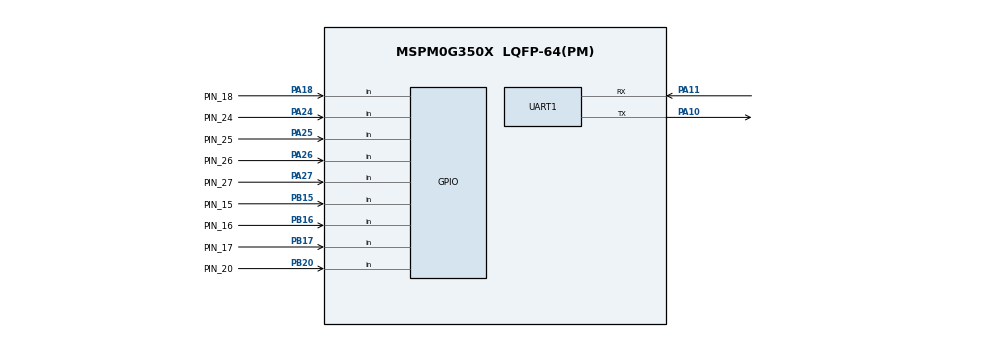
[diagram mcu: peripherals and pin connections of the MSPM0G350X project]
/**
 *
 * @cliArgs --device "MSPM0G350X" --part "Default" --package "LQFP-64(PM)" --product "mspm0_sdk@2.10.00.04"
 * @versions {"tool":"1.28.0+4696"}
 */

/**
 * Import the modules used in this configuration.
 */
const GPIO    = scripting.addModule("/ti/driverlib/GPIO", {}, false);
const GPIO1   = GPIO.addInstance();
const GPIO2   = GPIO.addInstance();
const GPIO3   = GPIO.addInstance();
const GPIO4   = GPIO.addInstance();
const GPIO5   = GPIO.addInstance();
const GPIO6   = GPIO.addInstance();
const GPIO7   = GPIO.addInstance();
const GPIO8   = GPIO.addInstance();
const GPIO9   = GPIO.addInstance();
const GPIO10  = GPIO.addInstance();
const SYSCTL  = scripting.addModule("/ti/driverlib/SYSCTL");
const SYSTICK = scripting.addModule("/ti/driverlib/SYSTICK");
const UART    = scripting.addModule("/ti/driverlib/UART", {}, false);
const UART1   = UART.addInstance();

/**
 * Write custom configuration values to the imported modules.
 */
const gate7  = system.clockTree["MFCLKGATE"];
gate7.enable = true;

GPIO1.$name                              = "LED1";
GPIO1.port                               = "PORTA";
GPIO1.associatedPins[0].$name            = "PIN_14";
GPIO1.associatedPins[0].internalResistor = "PULL_DOWN";
GPIO1.associatedPins[0].assignedPin      = "14";

const Board = scripting.addModule("/ti/driverlib/Board", {}, false);

GPIO2.$name                              = "KEY";
GPIO2.port                               = "PORTA";
GPIO2.associatedPins[0].$name            = "PIN_18";
GPIO2.associatedPins[0].direction        = "INPUT";
GPIO2.associatedPins[0].assignedPin      = "18";
GPIO2.associatedPins[0].internalResistor = "PULL_DOWN";
GPIO2.associatedPins[0].polarity         = "RISE";
GPIO2.associatedPins[0].interruptEn      = true;
GPIO2.associatedPins[0].pin.$assign      = "PA18";

GPIO3.port                               = "PORTA";
GPIO3.$name                              = "LineWalk_R1";
GPIO3.associatedPins[0].direction        = "INPUT";
GPIO3.associatedPins[0].internalResistor = "PULL_UP";
GPIO3.associatedPins[0].$name            = "PIN_24";
GPIO3.associatedPins[0].assignedPin      = "24";
GPIO3.associatedPins[0].pin.$assign      = "PA24";

GPIO4.port                               = "PORTA";
GPIO4.$name                              = "LineWalk_R2";
GPIO4.associatedPins[0].direction        = "INPUT";
GPIO4.associatedPins[0].internalResistor = "PULL_UP";
GPIO4.associatedPins[0].$name            = "PIN_25";
GPIO4.associatedPins[0].assignedPin      = "25";
GPIO4.associatedPins[0].pin.$assign      = "PA25";

GPIO5.port                               = "PORTA";
GPIO5.$name                              = "LineWalk_L2";
GPIO5.associatedPins[0].direction        = "INPUT";
GPIO5.associatedPins[0].internalResistor = "PULL_UP";
GPIO5.associatedPins[0].$name            = "PIN_26";
GPIO5.associatedPins[0].assignedPin      = "26";
GPIO5.associatedPins[0].pin.$assign      = "PA26";

GPIO6.port                               = "PORTA";
GPIO6.$name                              = "LineWalk_L1";
GPIO6.associatedPins[0].direction        = "INPUT";
GPIO6.associatedPins[0].internalResistor = "PULL_UP";
GPIO6.associatedPins[0].$name            = "PIN_27";
GPIO6.associatedPins[0].assignedPin      = "27";
GPIO6.associatedPins[0].pin.$assign      = "PA27";

GPIO7.port                               = "PORTB";
GPIO7.$name                              = "LineWalk_L3";
GPIO7.associatedPins[0].direction        = "INPUT";
GPIO7.associatedPins[0].internalResistor = "PULL_UP";
GPIO7.associatedPins[0].$name            = "PIN_15";
GPIO7.associatedPins[0].assignedPin      = "15";
GPIO7.associatedPins[0].pin.$assign      = "PB15";

GPIO8.port                               = "PORTB";
GPIO8.$name                              = "LineWalk_L4";
GPIO8.associatedPins[0].direction        = "INPUT";
GPIO8.associatedPins[0].internalResistor = "PULL_UP";
GPIO8.associatedPins[0].$name            = "PIN_16";
GPIO8.associatedPins[0].assignedPin      = "16";
GPIO8.associatedPins[0].pin.$assign      = "PB16";

GPIO9.port                               = "PORTB";
GPIO9.$name                              = "LineWalk_R3";
GPIO9.associatedPins[0].direction        = "INPUT";
GPIO9.associatedPins[0].internalResistor = "PULL_UP";
GPIO9.associatedPins[0].$name            = "PIN_17";
GPIO9.associatedPins[0].assignedPin      = "17";
GPIO9.associatedPins[0].pin.$assign      = "PB17";

GPIO10.port                               = "PORTB";
GPIO10.$name                              = "LineWalk_R4";
GPIO10.associatedPins[0].direction        = "INPUT";
GPIO10.associatedPins[0].internalResistor = "PULL_UP";
GPIO10.associatedPins[0].$name            = "PIN_20";
GPIO10.associatedPins[0].assignedPin      = "20";
GPIO10.associatedPins[0].pin.$assign      = "PB20";

SYSCTL.forceDefaultClkConfig = true;
SYSCTL.clockTreeEn           = true;

SYSTICK.periodEnable      = true;
SYSTICK.systickEnable     = true;
SYSTICK.interruptPriority = "0";
SYSTICK.period            = 32;

UART1.$name                    = "UART_0";
UART1.uartClkSrc               = "MFCLK";
UART1.enabledInterrupts        = ["RX"];
UART1.peripheral.$assign       = "UART0";
UART1.peripheral.rxPin.$assign = "PA11";
UART1.peripheral.txPin.$assign = "PA10";
UART1.txPinConfig.$name        = "ti_driverlib_gpio_GPIOPinGeneric0";
UART1.rxPinConfig.$name        = "ti_driverlib_gpio_GPIOPinGeneric1";

/**
 * Pinmux solution for unlocked pins/peripherals. This ensures that minor changes to the automatic solver in a future
 * version of the tool will not impact the pinmux you originally saw.  These lines can be completely deleted in order to
 * re-solve from scratch.
 */
GPIO1.associatedPins[0].pin.$suggestSolution = "PA14";
Board.peripheral.$suggestSolution            = "DEBUGSS";
Board.peripheral.swclkPin.$suggestSolution   = "PA20";
Board.peripheral.swdioPin.$suggestSolution   = "PA19";
